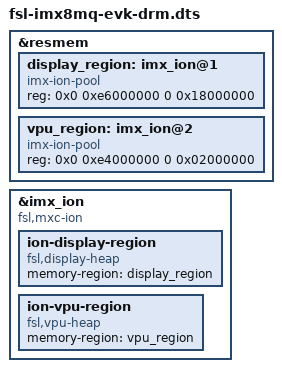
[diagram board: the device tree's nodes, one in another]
/*
 * Copyright 2017 NXP
 *
 * This program is free software; you can redistribute it and/or
 * modify it under the terms of the GNU General Public License
 * as published by the Free Software Foundation; either version 2
 * of the License, or (at your option) any later version.
 *
 * This program is distributed in the hope that it will be useful,
 * but WITHOUT ANY WARRANTY; without even the implied warranty of
 * MERCHANTABILITY or FITNESS FOR A PARTICULAR PURPOSE.  See the
 * GNU General Public License for more details.
 */

#include "fsl-imx8mq-evk.dts"

&resmem {
	display_region: imx_ion@1 {
		compatible = "imx-ion-pool";
		reg = <0x0 0xe6000000 0 0x18000000>;
	};

	vpu_region: imx_ion@2 {
		compatible = "imx-ion-pool";
		reg = <0x0 0xe4000000 0 0x02000000>;
	};
};

&imx_ion {
	compatible = "fsl,mxc-ion", "linux,ion";

	ion-display-region {
		compatible = "fsl,display-heap", "linux,ion-heap-unmapped";
		memory-region = <&display_region>;
	};

	ion-vpu-region {
		compatible = "fsl,vpu-heap", "linux,ion-heap-unmapped";
		memory-region = <&vpu_region>;
	};
};
